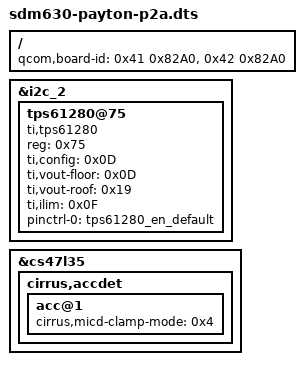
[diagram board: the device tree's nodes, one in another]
/* Copyright (c) 2017, The Linux Foundation. All rights reserved.
 *
 * This program is free software; you can redistribute it and/or modify
 * it under the terms of the GNU General Public License version 2 and
 * only version 2 as published by the Free Software Foundation.
 *
 * This program is distributed in the hope that it will be useful,
 * but WITHOUT ANY WARRANTY; without even the implied warranty of
 * MERCHANTABILITY or FITNESS FOR A PARTICULAR PURPOSE.  See the
 * GNU General Public License for more details.
 */


/dts-v1/;

#include "sdm630.dtsi"
#include "sdm630-payton.dtsi"

/ {
        qcom,board-id = <0x41 0x82A0>,<0x42 0x82A0>;
};

&i2c_2 { /* BLSP1 CAP SENSOR */
	status = "okay";
	tps61280@75 {
		compatible = "ti,tps61280";
		reg = <0x75>;
		ti,config = <0x0D>;
		ti,vout-floor = <0x0D>;
		ti,vout-roof = <0x19>;
		ti,ilim = <0x0F>;
		pinctrl-names = "default";
		pinctrl-0 = <&tps61280_en_default>;
	};
};

&cs47l35 {
	cirrus,accdet {
		acc@1 {
			/delete-property/ cirrus,jd-check-jd2;
			cirrus,micd-clamp-mode = <0x4>;
		};
	};
};
